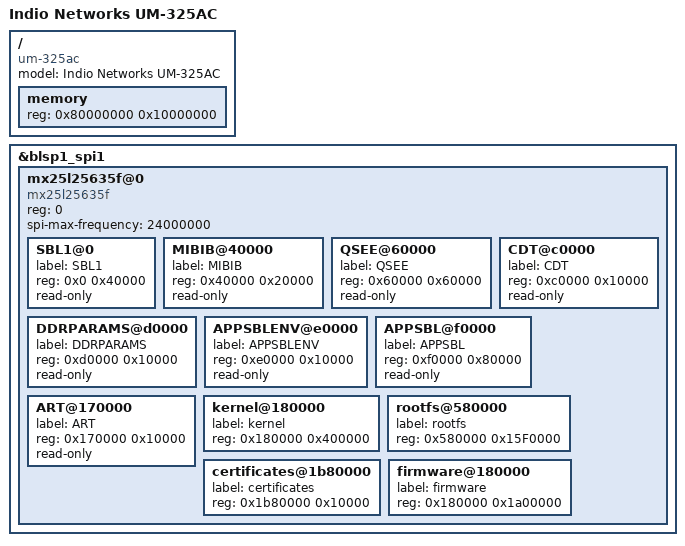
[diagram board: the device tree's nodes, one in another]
/* Copyright (c) 2015, The Linux Foundation. All rights reserved.
 *
 * Permission to use, copy, modify, and/or distribute this software for any
 * purpose with or without fee is hereby granted, provided that the above
 * copyright notice and this permission notice appear in all copies.
 *
 * THE SOFTWARE IS PROVIDED "AS IS" AND THE AUTHOR DISCLAIMS ALL WARRANTIES
 * WITH REGARD TO THIS SOFTWARE INCLUDING ALL IMPLIED WARRANTIES OF
 * MERCHANTABILITY AND FITNESS. IN NO EVENT SHALL THE AUTHOR BE LIABLE FOR
 * ANY SPECIAL, DIRECT, INDIRECT, OR CONSEQUENTIAL DAMAGES OR ANY DAMAGES
 * WHATSOEVER RESULTING FROM LOSS OF USE, DATA OR PROFITS, WHETHER IN AN
 * ACTION OF CONTRACT, NEGLIGENCE OR OTHER TORTIOUS ACTION, ARISING OUT OF
 * OR IN CONNECTION WITH THE USE OR PERFORMANCE OF THIS SOFTWARE.
 *
 */

#include "qcom-ipq4019-um-325ac.dtsi"

/ {
	model = "Indio Networks UM-325AC";
	compatible = "um-325ac";

	memory {
		device_type = "memory";
		reg = <0x80000000 0x10000000>;
	};
};

&blsp1_spi1 {
	mx25l25635f@0 {
		compatible = "mx25l25635f", "jedec,spi-nor";
		#address-cells = <1>;
		#size-cells = <1>;
		reg = <0>;
		spi-max-frequency = <24000000>;

		SBL1@0 {
			label = "SBL1";
			reg = <0x0 0x40000>;
			read-only;
		};
		MIBIB@40000 {
			label = "MIBIB";
			reg = <0x40000 0x20000>;
			read-only;
		};
		QSEE@60000 {
			label = "QSEE";
			reg = <0x60000 0x60000>;
			read-only;
		};
		CDT@c0000 {
			label = "CDT";
			reg = <0xc0000 0x10000>;
			read-only;
		};
		DDRPARAMS@d0000 {
			label = "DDRPARAMS";
			reg = <0xd0000 0x10000>;
			read-only;
		};
		APPSBLENV@e0000 {
			label = "APPSBLENV";
			reg = <0xe0000 0x10000>;
			read-only;
		};
		APPSBL@f0000 {
			label = "APPSBL";
			reg = <0xf0000 0x80000>;
			read-only;
		};
		ART@170000 {
			label = "ART";
			reg = <0x170000 0x10000>;
			read-only;
		};
		kernel@180000 {
			label = "kernel";
			reg = <0x180000 0x400000>;
		};
		rootfs@580000 {
			label = "rootfs";
			reg = <0x580000 0x15F0000>;
		};
		certificates@1b80000 {
			label = "certificates";
			reg = <0x1b80000 0x10000>;
		};
		firmware@180000 {
			label = "firmware";
			reg = <0x180000 0x1a00000>;
		};
	};
};
